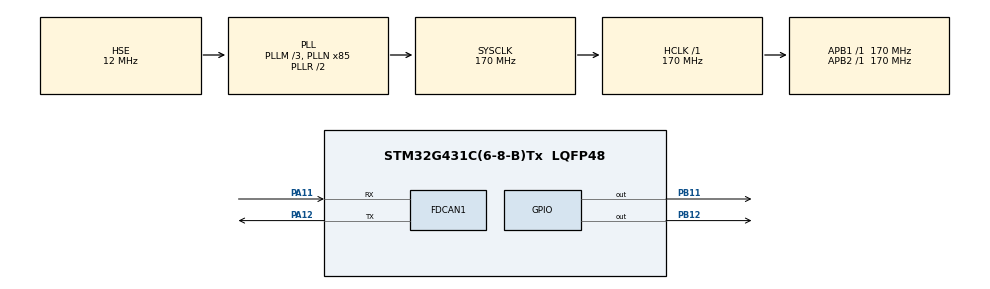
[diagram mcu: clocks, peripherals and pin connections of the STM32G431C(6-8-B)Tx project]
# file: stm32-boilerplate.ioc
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FDCAN1.CalculateBaudRateNominal=2125000
FDCAN1.CalculateTimeBitNominal=470
FDCAN1.CalculateTimeQuantumNominal=94.11764705882354
Mcu.Family=STM32G4
Mcu.Name=STM32G431C(6-8-B)Tx
Mcu.Package=LQFP48
NVIC.PriorityGroup=NVIC_PRIORITYGROUP_4
PA11.Mode=FDCAN_Activate
PA11.Signal=FDCAN1_RX
PA12.Mode=FDCAN_Activate
PA12.Signal=FDCAN1_TX
PB11.Signal=GPIO_Output
PB12.Signal=GPIO_Output
PF0-OSC_IN.Mode=HSE-External-Clock-Source
PF0-OSC_IN.Signal=RCC_OSC_IN
ProjectManager.HeapSize=0x200
ProjectManager.StackSize=0x400
ProjectManager.TargetToolchain=CMake
RCC.ADC12Freq_Value=170000000
RCC.AHBFreq_Value=170000000
RCC.APB1Freq_Value=170000000
RCC.APB1TimFreq_Value=170000000
RCC.APB2Freq_Value=170000000
RCC.APB2TimFreq_Value=170000000
RCC.CortexFreq_Value=170000000
RCC.EXTERNAL_CLOCK_VALUE=12288000
RCC.HCLKFreq_Value=170000000
RCC.HSE_VALUE=12000000
RCC.HSI48_VALUE=48000000
RCC.HSI_VALUE=16000000
RCC.LSE_VALUE=32768
RCC.PLLM=RCC_PLLM_DIV3
RCC.PLLN=85
RCC.PLLSourceVirtual=RCC_PLLSOURCE_HSE
RCC.SYSCLKFreq_VALUE=170000000
RCC.SYSCLKSource=RCC_SYSCLKSOURCE_PLLCLK
RCC.USBFreq_Value=170000000
RCC.VCOOutputFreq_Value=340000000
VP_SYS_VS_DBSignals.Mode=DisableDeadBatterySignals
board=custom

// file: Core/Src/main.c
/* USER CODE BEGIN Header */
/**
  ******************************************************************************
  * @file           : main.c
  * @brief          : Main program body
  ******************************************************************************
  * @attention
  *
  * Copyright (c) 2024 STMicroelectronics.
  * All rights reserved.
  *
  * This software is licensed under terms that can be found in the LICENSE file
  * in the root directory of this software component.
  * If no LICENSE file comes with this software, it is provided AS-IS.
  *
  ******************************************************************************
  */
/* USER CODE END Header */
#include "main.h"

FDCAN_HandleTypeDef hfdcan1;

void SystemClock_Config(void);
static void MX_GPIO_Init(void);
static void MX_FDCAN1_Init(void);

int main(void)
{

  /* MCU Configuration--------------------------------------------------------*/

  /* Reset of all peripherals, Initializes the Flash interface and the Systick. */
  HAL_Init();

  /* Configure the system clock */
  SystemClock_Config();

  /* Initialize all configured peripherals */
  MX_GPIO_Init();
  MX_FDCAN1_Init();
  /* USER CODE BEGIN 2 */
  HAL_FDCAN_Start(&hfdcan1);
  FDCAN_RxHeaderTypeDef messageHeader;
  uint8_t buffer[8] = {0};

  /* USER CODE END 2 */

  /* Infinite loop */
  while (1)
  {
    if(HAL_FDCAN_GetRxFifoFillLevel(&hfdcan1, 0) > 0){
      HAL_FDCAN_GetRxMessage(&hfdcan1, FDCAN_RX_FIFO0, &messageHeader, &buffer);
      HAL_GPIO_TogglePin(GPIOB, 11);
    }
  }
}

void SystemClock_Config(void)
{
  RCC_OscInitTypeDef RCC_OscInitStruct = {0};
  RCC_ClkInitTypeDef RCC_ClkInitStruct = {0};

  /** Configure the main internal regulator output voltage
  */
  HAL_PWREx_ControlVoltageScaling(PWR_REGULATOR_VOLTAGE_SCALE1_BOOST);

  /** Initializes the RCC Oscillators according to the specified parameters
  * in the RCC_OscInitTypeDef structure.
  */
  RCC_OscInitStruct.OscillatorType = RCC_OSCILLATORTYPE_HSE;
  RCC_OscInitStruct.HSEState = RCC_HSE_BYPASS;
  RCC_OscInitStruct.PLL.PLLState = RCC_PLL_ON;
  RCC_OscInitStruct.PLL.PLLSource = RCC_PLLSOURCE_HSE;
  RCC_OscInitStruct.PLL.PLLM = RCC_PLLM_DIV3;
  RCC_OscInitStruct.PLL.PLLN = 85;
  RCC_OscInitStruct.PLL.PLLP = RCC_PLLP_DIV2;
  RCC_OscInitStruct.PLL.PLLQ = RCC_PLLQ_DIV2;
  RCC_OscInitStruct.PLL.PLLR = RCC_PLLR_DIV2;
  if (HAL_RCC_OscConfig(&RCC_OscInitStruct) != HAL_OK)
  {
    Error_Handler();
  }

  /** Initializes the CPU, AHB and APB buses clocks
  */
  RCC_ClkInitStruct.ClockType = RCC_CLOCKTYPE_HCLK|RCC_CLOCKTYPE_SYSCLK
                              |RCC_CLOCKTYPE_PCLK1|RCC_CLOCKTYPE_PCLK2;
  RCC_ClkInitStruct.SYSCLKSource = RCC_SYSCLKSOURCE_PLLCLK;
  RCC_ClkInitStruct.AHBCLKDivider = RCC_SYSCLK_DIV1;
  RCC_ClkInitStruct.APB1CLKDivider = RCC_HCLK_DIV1;
  RCC_ClkInitStruct.APB2CLKDivider = RCC_HCLK_DIV1;

  if (HAL_RCC_ClockConfig(&RCC_ClkInitStruct, FLASH_LATENCY_4) != HAL_OK)
  {
    Error_Handler();
  }
}

static void MX_FDCAN1_Init(void)
{

  hfdcan1.Instance = FDCAN1;
  hfdcan1.Init.ClockDivider = FDCAN_CLOCK_DIV1;
  hfdcan1.Init.FrameFormat = FDCAN_FRAME_CLASSIC;
  hfdcan1.Init.Mode = FDCAN_MODE_NORMAL;
  hfdcan1.Init.AutoRetransmission = DISABLE;
  hfdcan1.Init.TransmitPause = DISABLE;
  hfdcan1.Init.ProtocolException = DISABLE;
  hfdcan1.Init.NominalPrescaler = 16;
  hfdcan1.Init.NominalSyncJumpWidth = 1;
  hfdcan1.Init.NominalTimeSeg1 = 2;
  hfdcan1.Init.NominalTimeSeg2 = 2;
  hfdcan1.Init.DataPrescaler = 1;
  hfdcan1.Init.DataSyncJumpWidth = 1;
  hfdcan1.Init.DataTimeSeg1 = 1;
  hfdcan1.Init.DataTimeSeg2 = 1;
  hfdcan1.Init.StdFiltersNbr = 0;
  hfdcan1.Init.ExtFiltersNbr = 0;
  hfdcan1.Init.TxFifoQueueMode = FDCAN_TX_FIFO_OPERATION;
  if (HAL_FDCAN_Init(&hfdcan1) != HAL_OK)
  {
    Error_Handler();
  }

}

static void MX_GPIO_Init(void)
{
  GPIO_InitTypeDef GPIO_InitStruct = {0};

  /* GPIO Ports Clock Enable */
  __HAL_RCC_GPIOF_CLK_ENABLE();
  __HAL_RCC_GPIOB_CLK_ENABLE();
  __HAL_RCC_GPIOA_CLK_ENABLE();

  /*Configure GPIO pin Output Level */
  HAL_GPIO_WritePin(GPIOB, GPIO_PIN_11|GPIO_PIN_12, GPIO_PIN_RESET);

  /*Configure GPIO pins : PB11 PB12 */
  GPIO_InitStruct.Pin = GPIO_PIN_11|GPIO_PIN_12;
  GPIO_InitStruct.Mode = GPIO_MODE_OUTPUT_PP;
  GPIO_InitStruct.Pull = GPIO_NOPULL;
  GPIO_InitStruct.Speed = GPIO_SPEED_FREQ_LOW;
  HAL_GPIO_Init(GPIOB, &GPIO_InitStruct);

}

void Error_Handler(void)
{
  __disable_irq();
  while (1)
  {
  }
}
